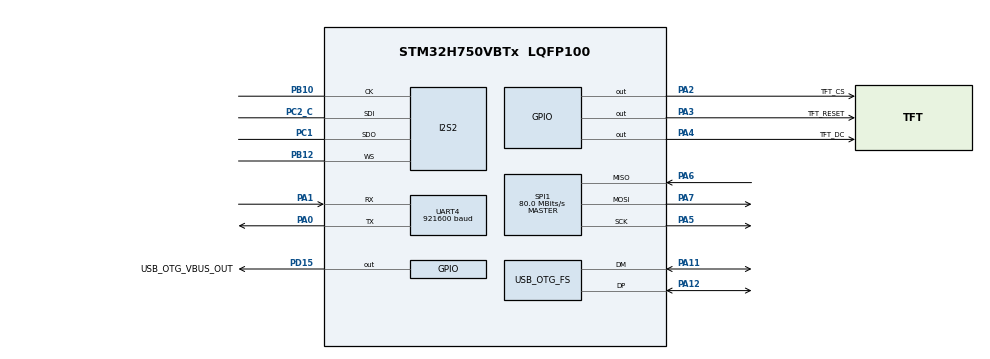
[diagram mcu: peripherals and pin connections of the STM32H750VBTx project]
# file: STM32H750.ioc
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CORTEX_M7.AccessPermission-Cortex_Memory_Protection_Unit_Region0_Settings=MPU_REGION_FULL_ACCESS
CORTEX_M7.AccessPermission-Cortex_Memory_Protection_Unit_Region1_Settings=MPU_REGION_FULL_ACCESS
CORTEX_M7.BaseAddress-Cortex_Memory_Protection_Unit_Region0_Settings=0x90000000
CORTEX_M7.BaseAddress-Cortex_Memory_Protection_Unit_Region1_Settings=0x90000000
CORTEX_M7.CPU_DCache=Enabled
CORTEX_M7.CPU_ICache=Enabled
CORTEX_M7.DisableExec-Cortex_Memory_Protection_Unit_Region0_Settings=MPU_INSTRUCTION_ACCESS_DISABLE
CORTEX_M7.Enable-Cortex_Memory_Protection_Unit_Region0_Settings=MPU_REGION_ENABLE
CORTEX_M7.Enable-Cortex_Memory_Protection_Unit_Region1_Settings=MPU_REGION_ENABLE
CORTEX_M7.IsBufferable-Cortex_Memory_Protection_Unit_Region0_Settings=MPU_ACCESS_BUFFERABLE
CORTEX_M7.IsBufferable-Cortex_Memory_Protection_Unit_Region1_Settings=MPU_ACCESS_BUFFERABLE
CORTEX_M7.IsCacheable-Cortex_Memory_Protection_Unit_Region0_Settings=MPU_ACCESS_CACHEABLE
CORTEX_M7.IsCacheable-Cortex_Memory_Protection_Unit_Region1_Settings=MPU_ACCESS_CACHEABLE
CORTEX_M7.MPU_Control=MPU_PRIVILEGED_DEFAULT
CORTEX_M7.Size-Cortex_Memory_Protection_Unit_Region0_Settings=MPU_REGION_SIZE_8MB
CORTEX_M7.Size-Cortex_Memory_Protection_Unit_Region1_Settings=MPU_REGION_SIZE_1MB
Dma.Request0=SPI1_TX
Dma.Request1=SPI2_RX
Dma.Request2=SPI2_TX
Dma.Request3=SPI1_RX
Dma.Request4=UART4_RX
Dma.Request5=UART4_TX
Dma.SPI1_RX.3.Direction=DMA_PERIPH_TO_MEMORY
Dma.SPI1_RX.3.EventEnable=DISABLE
Dma.SPI1_RX.3.FIFOMode=DMA_FIFOMODE_DISABLE
Dma.SPI1_RX.3.Instance=DMA2_Stream1
Dma.SPI1_RX.3.MemDataAlignment=DMA_MDATAALIGN_BYTE
Dma.SPI1_RX.3.MemInc=DMA_MINC_ENABLE
Dma.SPI1_RX.3.Mode=DMA_NORMAL
Dma.SPI1_RX.3.PeriphDataAlignment=DMA_PDATAALIGN_BYTE
Dma.SPI1_RX.3.PeriphInc=DMA_PINC_DISABLE
Dma.SPI1_RX.3.Polarity=HAL_DMAMUX_REQ_GEN_RISING
Dma.SPI1_RX.3.Priority=DMA_PRIORITY_HIGH
Dma.SPI1_RX.3.RequestNumber=1
Dma.SPI1_RX.3.SignalID=NONE
Dma.SPI1_RX.3.SyncEnable=DISABLE
Dma.SPI1_RX.3.SyncPolarity=HAL_DMAMUX_SYNC_NO_EVENT
Dma.SPI1_RX.3.SyncRequestNumber=1
Dma.SPI1_RX.3.SyncSignalID=NONE
Dma.SPI1_TX.0.Direction=DMA_MEMORY_TO_PERIPH
Dma.SPI1_TX.0.EventEnable=DISABLE
Dma.SPI1_TX.0.FIFOMode=DMA_FIFOMODE_DISABLE
Dma.SPI1_TX.0.Instance=DMA2_Stream2
Dma.SPI1_TX.0.MemDataAlignment=DMA_MDATAALIGN_BYTE
Dma.SPI1_TX.0.MemInc=DMA_MINC_ENABLE
Dma.SPI1_TX.0.Mode=DMA_NORMAL
Dma.SPI1_TX.0.PeriphDataAlignment=DMA_PDATAALIGN_BYTE
Dma.SPI1_TX.0.PeriphInc=DMA_PINC_DISABLE
Dma.SPI1_TX.0.Polarity=HAL_DMAMUX_REQ_GEN_RISING
Dma.SPI1_TX.0.Priority=DMA_PRIORITY_HIGH
Dma.SPI1_TX.0.RequestNumber=1
Dma.SPI1_TX.0.SignalID=NONE
Dma.SPI1_TX.0.SyncEnable=DISABLE
Dma.SPI1_TX.0.SyncPolarity=HAL_DMAMUX_SYNC_NO_EVENT
Dma.SPI1_TX.0.SyncRequestNumber=1
Dma.SPI1_TX.0.SyncSignalID=NONE
Dma.SPI2_RX.1.Direction=DMA_PERIPH_TO_MEMORY
Dma.SPI2_RX.1.EventEnable=DISABLE
Dma.SPI2_RX.1.FIFOMode=DMA_FIFOMODE_DISABLE
Dma.SPI2_RX.1.Instance=DMA1_Stream1
Dma.SPI2_RX.1.MemDataAlignment=DMA_MDATAALIGN_HALFWORD
Dma.SPI2_RX.1.MemInc=DMA_MINC_ENABLE
Dma.SPI2_RX.1.Mode=DMA_CIRCULAR
Dma.SPI2_RX.1.PeriphDataAlignment=DMA_PDATAALIGN_HALFWORD
Dma.SPI2_RX.1.PeriphInc=DMA_PINC_DISABLE
Dma.SPI2_RX.1.Polarity=HAL_DMAMUX_REQ_GEN_RISING
Dma.SPI2_RX.1.Priority=DMA_PRIORITY_VERY_HIGH
Dma.SPI2_RX.1.RequestNumber=1
Dma.SPI2_RX.1.SignalID=NONE
Dma.SPI2_RX.1.SyncEnable=DISABLE
Dma.SPI2_RX.1.SyncPolarity=HAL_DMAMUX_SYNC_NO_EVENT
Dma.SPI2_RX.1.SyncRequestNumber=1
Dma.SPI2_RX.1.SyncSignalID=NONE
Dma.SPI2_TX.2.Direction=DMA_MEMORY_TO_PERIPH
Dma.SPI2_TX.2.EventEnable=DISABLE
Dma.SPI2_TX.2.FIFOMode=DMA_FIFOMODE_DISABLE
Dma.SPI2_TX.2.Instance=DMA1_Stream2
Dma.SPI2_TX.2.MemDataAlignment=DMA_MDATAALIGN_HALFWORD
Dma.SPI2_TX.2.MemInc=DMA_MINC_ENABLE
Dma.SPI2_TX.2.Mode=DMA_CIRCULAR
Dma.SPI2_TX.2.PeriphDataAlignment=DMA_PDATAALIGN_HALFWORD
Dma.SPI2_TX.2.PeriphInc=DMA_PINC_DISABLE
Dma.SPI2_TX.2.Polarity=HAL_DMAMUX_REQ_GEN_RISING
Dma.SPI2_TX.2.Priority=DMA_PRIORITY_VERY_HIGH
Dma.SPI2_TX.2.RequestNumber=1
Dma.SPI2_TX.2.SignalID=NONE
Dma.SPI2_TX.2.SyncEnable=DISABLE
Dma.SPI2_TX.2.SyncPolarity=HAL_DMAMUX_SYNC_NO_EVENT
Dma.SPI2_TX.2.SyncRequestNumber=1
Dma.SPI2_TX.2.SyncSignalID=NONE
Dma.UART4_RX.4.Direction=DMA_PERIPH_TO_MEMORY
Dma.UART4_RX.4.EventEnable=DISABLE
Dma.UART4_RX.4.FIFOMode=DMA_FIFOMODE_DISABLE
Dma.UART4_RX.4.Instance=DMA1_Stream0
Dma.UART4_RX.4.MemDataAlignment=DMA_MDATAALIGN_BYTE
Dma.UART4_RX.4.MemInc=DMA_MINC_ENABLE
Dma.UART4_RX.4.Mode=DMA_NORMAL
Dma.UART4_RX.4.PeriphDataAlignment=DMA_PDATAALIGN_BYTE
Dma.UART4_RX.4.PeriphInc=DMA_PINC_DISABLE
Dma.UART4_RX.4.Polarity=HAL_DMAMUX_REQ_GEN_RISING
Dma.UART4_RX.4.Priority=DMA_PRIORITY_LOW
Dma.UART4_RX.4.RequestNumber=1
Dma.UART4_RX.4.SignalID=NONE
Dma.UART4_RX.4.SyncEnable=DISABLE
Dma.UART4_RX.4.SyncPolarity=HAL_DMAMUX_SYNC_NO_EVENT
Dma.UART4_RX.4.SyncRequestNumber=1
Dma.UART4_RX.4.SyncSignalID=NONE
Dma.UART4_TX.5.Direction=DMA_MEMORY_TO_PERIPH
Dma.UART4_TX.5.EventEnable=DISABLE
Dma.UART4_TX.5.FIFOMode=DMA_FIFOMODE_DISABLE
Dma.UART4_TX.5.Instance=DMA1_Stream3
Dma.UART4_TX.5.MemDataAlignment=DMA_MDATAALIGN_BYTE
Dma.UART4_TX.5.MemInc=DMA_MINC_ENABLE
Dma.UART4_TX.5.Mode=DMA_NORMAL
Dma.UART4_TX.5.PeriphDataAlignment=DMA_PDATAALIGN_BYTE
Dma.UART4_TX.5.PeriphInc=DMA_PINC_DISABLE
Dma.UART4_TX.5.Polarity=HAL_DMAMUX_REQ_GEN_RISING
Dma.UART4_TX.5.Priority=DMA_PRIORITY_LOW
Dma.UART4_TX.5.RequestNumber=1
Dma.UART4_TX.5.SignalID=NONE
Dma.UART4_TX.5.SyncEnable=DISABLE
Dma.UART4_TX.5.SyncPolarity=HAL_DMAMUX_SYNC_NO_EVENT
Dma.UART4_TX.5.SyncRequestNumber=1
Dma.UART4_TX.5.SyncSignalID=NONE
FREERTOS.Tasks01=defaultTask,24,128,StartDefaultTask,Default,NULL,Dynamic,NULL,NULL
I2S2.AudioFreq=AudioFreqCustomValue
I2S2.AudioFreqCustom=44100
I2S2.ErrorAudioFreq=-0.32 %
I2S2.Instance=SPI$Index
I2S2.RealAudioFreq=43.859 KHz
Mcu.Family=STM32H7
Mcu.Name=STM32H750VBTx
Mcu.Package=LQFP100
NVIC.DMA1_Stream0_IRQn=true\:5\:0\:false\:false\:true\:true\:false\:true\:true
NVIC.DMA1_Stream1_IRQn=true\:5\:0\:false\:false\:true\:true\:false\:true\:true
NVIC.DMA1_Stream2_IRQn=true\:5\:0\:false\:false\:true\:true\:false\:true\:true
NVIC.DMA1_Stream3_IRQn=true\:5\:0\:false\:false\:true\:true\:false\:true\:true
NVIC.DMA2_Stream1_IRQn=true\:5\:0\:false\:false\:true\:false\:false\:true\:true
NVIC.DMA2_Stream2_IRQn=true\:5\:0\:false\:false\:true\:false\:false\:true\:true
NVIC.OTG_FS_IRQn=true\:5\:0\:false\:false\:true\:true\:true\:true\:true
NVIC.PriorityGroup=NVIC_PRIORITYGROUP_4
NVIC.SPI1_IRQn=true\:5\:0\:false\:false\:true\:true\:true\:true\:true
NVIC.SPI2_IRQn=true\:5\:0\:false\:false\:true\:true\:true\:true\:true
NVIC.TIM5_IRQn=true\:15\:0\:false\:false\:true\:false\:false\:true\:true
NVIC.TimeBase=TIM5_IRQn
NVIC.TimeBaseIP=TIM5
NVIC.UART4_IRQn=true\:5\:0\:false\:false\:true\:true\:true\:true\:true
PA0.Mode=Asynchronous
PA0.Signal=UART4_TX
PA1.Mode=Asynchronous
PA1.Signal=UART4_RX
PA11.GPIO_Speed=GPIO_SPEED_FREQ_VERY_HIGH
PA11.Mode=Host_Only
PA11.Signal=USB_OTG_FS_DM
PA12.GPIO_Speed=GPIO_SPEED_FREQ_VERY_HIGH
PA12.Mode=Host_Only
PA12.Signal=USB_OTG_FS_DP
PA13\ (JTMS/SWDIO).Mode=Serial_Wire
PA13\ (JTMS/SWDIO).Signal=DEBUG_JTMS-SWDIO
PA14\ (JTCK/SWCLK).Mode=Serial_Wire
PA14\ (JTCK/SWCLK).Signal=DEBUG_JTCK-SWCLK
PA2.GPIO_Label=TFT_CS
PA2.GPIO_Speed=GPIO_SPEED_FREQ_HIGH
PA2.Signal=GPIO_Output
PA3.GPIO_Label=TFT_RESET
PA3.Signal=GPIO_Output
PA4.GPIO_Label=TFT_DC
PA4.GPIO_Speed=GPIO_SPEED_FREQ_HIGH
PA4.PinState=GPIO_PIN_RESET
PA4.Signal=GPIO_Output
PA5.GPIO_Speed=GPIO_SPEED_FREQ_VERY_HIGH
PA5.Mode=Full_Duplex_Master
PA5.Signal=SPI1_SCK
PA6.GPIO_Speed=GPIO_SPEED_FREQ_VERY_HIGH
PA6.Mode=Full_Duplex_Master
PA6.Signal=SPI1_MISO
PA7.GPIO_Speed=GPIO_SPEED_FREQ_VERY_HIGH
PA7.Mode=Full_Duplex_Master
PA7.Signal=SPI1_MOSI
PB10.GPIO_Speed=GPIO_SPEED_FREQ_VERY_HIGH
PB10.Mode=Full_Duplex_Master
PB10.Signal=I2S2_CK
PB12.GPIO_Speed=GPIO_SPEED_FREQ_VERY_HIGH
PB12.Mode=Full_Duplex_Master
PB12.Signal=I2S2_WS
PC1.GPIO_Speed=GPIO_SPEED_FREQ_VERY_HIGH
PC1.Mode=Full_Duplex_Master
PC1.Signal=I2S2_SDO
PC14-OSC32_IN\ (OSC32_IN).Mode=LSE-External-Oscillator
PC14-OSC32_IN\ (OSC32_IN).Signal=RCC_OSC32_IN
PC15-OSC32_OUT\ (OSC32_OUT).Mode=LSE-External-Oscillator
PC15-OSC32_OUT\ (OSC32_OUT).Signal=RCC_OSC32_OUT
PC2_C.GPIO_Speed=GPIO_SPEED_FREQ_VERY_HIGH
PC2_C.Mode=Full_Duplex_Master
PC2_C.Signal=I2S2_SDI
PD13.Signal=QUADSPI_BK1_IO3
PD15.GPIO_Label=USB_OTG_VBUS_OUT
PD15.Signal=GPIO_Output
PH0-OSC_IN\ (PH0).Mode=HSE-External-Oscillator
PH0-OSC_IN\ (PH0).Signal=RCC_OSC_IN
PH1-OSC_OUT\ (PH1).Mode=HSE-External-Oscillator
PH1-OSC_OUT\ (PH1).Signal=RCC_OSC_OUT
ProjectManager.HeapSize=0x200
ProjectManager.StackSize=0x800
ProjectManager.TargetToolchain=Makefile
RCC.ADCFreq_Value=160000000
RCC.APB1Freq_Value=120000000
RCC.APB2Freq_Value=120000000
RCC.APB3Freq_Value=120000000
RCC.APB4Freq_Value=120000000
RCC.CortexFreq_Value=480000000
RCC.D1PPRE=RCC_APB3_DIV2
RCC.D2PPRE1=RCC_APB1_DIV2
RCC.D2PPRE2=RCC_APB2_DIV2
RCC.D3PPRE=RCC_APB4_DIV2
RCC.DIVM1=5
RCC.DIVM2=5
RCC.DIVN1=192
RCC.DIVN2=64
RCC.DIVQ1=15
RCC.HCLKFreq_Value=240000000
RCC.HPRE=RCC_HCLK_DIV2
RCC.PLL2FRACN=0
RCC.PLL3FRACN=0
RCC.PLLFRACN=0
RCC.PLLSourceVirtual=RCC_PLLSOURCE_HSE
RCC.SPI123CLockSelection=RCC_SPI123CLKSOURCE_PLL2
RCC.SYSCLKFreq_VALUE=480000000
RCC.SYSCLKSource=RCC_SYSCLKSOURCE_PLLCLK
RCC.USBFreq_Value=64000000
SPI1.BaudRatePrescaler=SPI_BAUDRATEPRESCALER_2
SPI1.CalculateBaudRate=80.0 MBits/s
SPI1.DataSize=SPI_DATASIZE_8BIT
SPI1.Direction=SPI_DIRECTION_2LINES
SPI1.Mode=SPI_MODE_MASTER
SPI1.NSSPMode=SPI_NSS_PULSE_DISABLE
SPI1.VirtualType=VM_MASTER
UART4.BaudRate=921600
USB_HOST.BSP.number=1
USB_HOST.USBH_DEBUG_LEVEL-ALL_Classes_FS=3
USB_HOST.USBH_HandleTypeDef-ALL_Classes_FS=hUsbHostFS
USB_HOST.USBH_PROCESS_STACK_SIZE-ALL_Classes_FS=2*1024
USB_HOST.VirtualModeFS=All_Classes
USB_HOST0.BSP.STBoard=false
USB_HOST0.BSP.api=Unknown
USB_HOST0.BSP.condition=ALL_SW_VBUS_DRIVE_FS \= false
USB_HOST0.BSP.instance=PD15
USB_HOST0.BSP.ip=GPIO
USB_HOST0.BSP.mode=Output
USB_HOST0.BSP.name=Drive_VBUS_FS
USB_HOST0.BSP.solution=PD15
USB_OTG_FS.VirtualMode=Host_Only
USB_OTG_FS.dma_enable=ENABLE
USB_OTG_FS.phy_itface=HCD_PHY_EMBEDDED
VP_FREERTOS_VS_CMSIS_V2.Mode=CMSIS_V2
VP_SYS_VS_tim5.Mode=TIM5
VP_USB_HOST_VS_USB_HOST_ALL_CLASS_FS.Mode=ALL_Classes_FS
board=custom

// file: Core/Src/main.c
/* USER CODE BEGIN Header */
/**
  ******************************************************************************
  * @file           : main.c
  * @brief          : Main program body
  ******************************************************************************
  * @attention
  *
  * Copyright (c) 2023 STMicroelectronics.
  * All rights reserved.
  *
  * This software is licensed under terms that can be found in the LICENSE file
  * in the root directory of this software component.
  * If no LICENSE file comes with this software, it is provided AS-IS.
  *
  ******************************************************************************
  */
/* USER CODE END Header */
#include "main.h"
#include "cmsis_os2.h"
#include "dma.h"
#include "i2s.h"
#include "spi.h"
#include "usart.h"
#include "usb_host.h"
#include "gpio.h"

/* USER CODE BEGIN Includes */
#include "ILI9341/ili9341.h"
#include "m8ec/m8ec.h"
#include "SEGGER_SYSVIEW.h"
#include "ucprof/ucprof.h"
/* USER CODE END Includes */

void SystemClock_Config(void);
void PeriphCommonClock_Config(void);
static void MPU_Config(void);
void MX_FREERTOS_Init(void);

int main(void)
{
  /* USER CODE BEGIN 1 */
  SEGGER_SYSVIEW_Conf();
  ucprof_init();
  /* USER CODE END 1 */

  /* MPU Configuration--------------------------------------------------------*/
  MPU_Config();
/* Enable the CPU Cache */

  /* Enable I-Cache---------------------------------------------------------*/
  SCB_EnableICache();

  /* MCU Configuration--------------------------------------------------------*/

  /* Reset of all peripherals, Initializes the Flash interface and the Systick. */
  HAL_Init();

  /* Configure the system clock */
  SystemClock_Config();

/* Configure the peripherals common clocks */
  PeriphCommonClock_Config();

  /* Initialize all configured peripherals */
  MX_GPIO_Init();
  MX_DMA_Init();
  MX_SPI1_Init();
  MX_I2S2_Init();
  MX_UART4_Init();

  /* Init scheduler */
  osKernelInitialize();

  /* Call init function for freertos objects (in freertos.c) */
  MX_FREERTOS_Init();

  /* Start scheduler */
  osKernelStart();

  /* We should never get here as control is now taken by the scheduler */
  /* Infinite loop */
  while (1)
  {

  }
}

void SystemClock_Config(void)
{
  RCC_OscInitTypeDef RCC_OscInitStruct = {0};
  RCC_ClkInitTypeDef RCC_ClkInitStruct = {0};

  /** Supply configuration update enable
  */
  HAL_PWREx_ConfigSupply(PWR_LDO_SUPPLY);

  /** Configure the main internal regulator output voltage
  */
  __HAL_PWR_VOLTAGESCALING_CONFIG(PWR_REGULATOR_VOLTAGE_SCALE1);

  while(!__HAL_PWR_GET_FLAG(PWR_FLAG_VOSRDY)) {}

  __HAL_RCC_SYSCFG_CLK_ENABLE();
  __HAL_PWR_VOLTAGESCALING_CONFIG(PWR_REGULATOR_VOLTAGE_SCALE0);

  while(!__HAL_PWR_GET_FLAG(PWR_FLAG_VOSRDY)) {}

  /** Initializes the RCC Oscillators according to the specified parameters
  * in the RCC_OscInitTypeDef structure.
  */
  RCC_OscInitStruct.OscillatorType = RCC_OSCILLATORTYPE_HSE;
  RCC_OscInitStruct.HSEState = RCC_HSE_ON;
  RCC_OscInitStruct.PLL.PLLState = RCC_PLL_ON;
  RCC_OscInitStruct.PLL.PLLSource = RCC_PLLSOURCE_HSE;
  RCC_OscInitStruct.PLL.PLLM = 5;
  RCC_OscInitStruct.PLL.PLLN = 192;
  RCC_OscInitStruct.PLL.PLLP = 2;
  RCC_OscInitStruct.PLL.PLLQ = 15;
  RCC_OscInitStruct.PLL.PLLR = 2;
  RCC_OscInitStruct.PLL.PLLRGE = RCC_PLL1VCIRANGE_2;
  RCC_OscInitStruct.PLL.PLLVCOSEL = RCC_PLL1VCOWIDE;
  RCC_OscInitStruct.PLL.PLLFRACN = 0;
  if (HAL_RCC_OscConfig(&RCC_OscInitStruct) != HAL_OK)
  {
    Error_Handler();
  }

  /** Initializes the CPU, AHB and APB buses clocks
  */
  RCC_ClkInitStruct.ClockType = RCC_CLOCKTYPE_HCLK|RCC_CLOCKTYPE_SYSCLK
                              |RCC_CLOCKTYPE_PCLK1|RCC_CLOCKTYPE_PCLK2
                              |RCC_CLOCKTYPE_D3PCLK1|RCC_CLOCKTYPE_D1PCLK1;
  RCC_ClkInitStruct.SYSCLKSource = RCC_SYSCLKSOURCE_PLLCLK;
  RCC_ClkInitStruct.SYSCLKDivider = RCC_SYSCLK_DIV1;
  RCC_ClkInitStruct.AHBCLKDivider = RCC_HCLK_DIV2;
  RCC_ClkInitStruct.APB3CLKDivider = RCC_APB3_DIV2;
  RCC_ClkInitStruct.APB1CLKDivider = RCC_APB1_DIV2;
  RCC_ClkInitStruct.APB2CLKDivider = RCC_APB2_DIV2;
  RCC_ClkInitStruct.APB4CLKDivider = RCC_APB4_DIV2;

  if (HAL_RCC_ClockConfig(&RCC_ClkInitStruct, FLASH_LATENCY_4) != HAL_OK)
  {
    Error_Handler();
  }
}

void PeriphCommonClock_Config(void)
{
  RCC_PeriphCLKInitTypeDef PeriphClkInitStruct = {0};

  /** Initializes the peripherals clock
  */
  PeriphClkInitStruct.PeriphClockSelection = RCC_PERIPHCLK_SPI2|RCC_PERIPHCLK_SPI1;
  PeriphClkInitStruct.PLL2.PLL2M = 5;
  PeriphClkInitStruct.PLL2.PLL2N = 64;
  PeriphClkInitStruct.PLL2.PLL2P = 2;
  PeriphClkInitStruct.PLL2.PLL2Q = 2;
  PeriphClkInitStruct.PLL2.PLL2R = 2;
  PeriphClkInitStruct.PLL2.PLL2RGE = RCC_PLL2VCIRANGE_2;
  PeriphClkInitStruct.PLL2.PLL2VCOSEL = RCC_PLL2VCOWIDE;
  PeriphClkInitStruct.PLL2.PLL2FRACN = 0;
  PeriphClkInitStruct.Spi123ClockSelection = RCC_SPI123CLKSOURCE_PLL2;
  if (HAL_RCCEx_PeriphCLKConfig(&PeriphClkInitStruct) != HAL_OK)
  {
    Error_Handler();
  }
}

/* USER CODE BEGIN 4 */
uint16_t audio_out_buffer[256];
/* USER CODE END 4 */

/* MPU Configuration */

void MPU_Config(void)
{
  MPU_Region_InitTypeDef MPU_InitStruct = {0};

  /* Disables the MPU */
  HAL_MPU_Disable();

  /** Initializes and configures the Region and the memory to be protected
  */
  MPU_InitStruct.Enable = MPU_REGION_ENABLE;
  MPU_InitStruct.Number = MPU_REGION_NUMBER0;
  MPU_InitStruct.BaseAddress = 0x90000000;
  MPU_InitStruct.Size = MPU_REGION_SIZE_8MB;
  MPU_InitStruct.SubRegionDisable = 0x0;
  MPU_InitStruct.TypeExtField = MPU_TEX_LEVEL0;
  MPU_InitStruct.AccessPermission = MPU_REGION_FULL_ACCESS;
  MPU_InitStruct.DisableExec = MPU_INSTRUCTION_ACCESS_DISABLE;
  MPU_InitStruct.IsShareable = MPU_ACCESS_NOT_SHAREABLE;
  MPU_InitStruct.IsCacheable = MPU_ACCESS_CACHEABLE;
  MPU_InitStruct.IsBufferable = MPU_ACCESS_BUFFERABLE;

  HAL_MPU_ConfigRegion(&MPU_InitStruct);

  /** Initializes and configures the Region and the memory to be protected
  */
  MPU_InitStruct.Number = MPU_REGION_NUMBER1;
  MPU_InitStruct.Size = MPU_REGION_SIZE_1MB;
  MPU_InitStruct.DisableExec = MPU_INSTRUCTION_ACCESS_ENABLE;

  HAL_MPU_ConfigRegion(&MPU_InitStruct);
  /* Enables the MPU */
  HAL_MPU_Enable(MPU_PRIVILEGED_DEFAULT);

}

void HAL_TIM_PeriodElapsedCallback(TIM_HandleTypeDef *htim)
{
  if (htim->Instance == TIM5) {
    HAL_IncTick();
  }
}

void Error_Handler(void)
{
  __disable_irq();
  while (1)
  {
  }
}

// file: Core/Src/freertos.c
/* USER CODE BEGIN Header */
/**
  ******************************************************************************
  * File Name          : freertos.c
  * Description        : Code for freertos applications
  ******************************************************************************
  * @attention
  *
  * Copyright (c) 2023 STMicroelectronics.
  * All rights reserved.
  *
  * This software is licensed under terms that can be found in the LICENSE file
  * in the root directory of this software component.
  * If no LICENSE file comes with this software, it is provided AS-IS.
  *
  ******************************************************************************
  */
/* USER CODE END Header */

#include "FreeRTOS.h"
#include "task.h"
#include "main.h"
#include "cmsis_os.h"

/* USER CODE BEGIN Includes */
#include "m8ec/m8ec.h"

#include "usb_host.h"

#include "SEGGER_SYSVIEW.h"

/* USER CODE END Includes */

/* Definitions for startupTask */
osThreadId_t startupTaskHandle;
const osThreadAttr_t startupTask_attributes = {
  .name = "startup",
  .stack_size = 4 * 1024,
  .priority = (osPriority_t) osPriorityRealtime,
};

void startupTask(void *argument);

extern void MX_USB_HOST_Init(void);
void MX_FREERTOS_Init(void); /* (MISRA C 2004 rule 8.1) */

void MX_FREERTOS_Init(void) {

  /* Create the thread(s) */
  /* creation of startupTask */
  startupTaskHandle = osThreadNew(startupTask, NULL, &startupTask_attributes);

}

void startupTask(void *arg)
{
  UNUSED(arg);
  SEGGER_SYSVIEW_Start();
  /* init code for USB_HOST */
  MX_USB_HOST_Init();
  /* USER CODE BEGIN 5 */
  m8ec_launch();
//  static uint16_t audio_out_buffer[256];
//  HAL_I2S_Transmit_DMA(&hi2s2, audio_out_buffer, 256);
  osThreadTerminate(startupTaskHandle);
  /* USER CODE END 5 */
}
